# sysctl register map
Vendor: Texas Instruments
Peripheral module from a debugger description file (folder tm4e129xnczad).
Registers are 32-bit, read-write, no defined reset value unless marked. A register's access mark holds for its fields unless they carry their own. Offsets are as the file gives them; lines under a group give offsets from that group; [hi:lo] are bit positions; {n}, {i} and the like mark numbered series; 'fields as' and 'values as' point back to an identical list; <NAME> marks a mode.

## SYSCTL — System Control register addresses
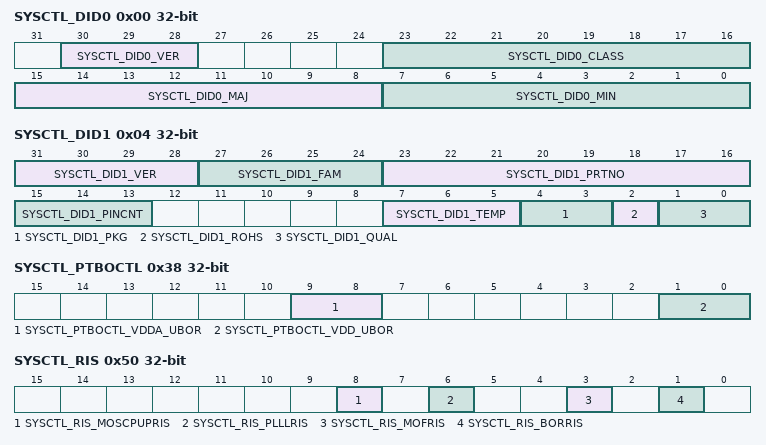
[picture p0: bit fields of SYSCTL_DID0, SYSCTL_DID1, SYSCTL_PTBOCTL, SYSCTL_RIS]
0x00 SYSCTL_DID0 ro — Device Identification 0
  [30:28] SYSCTL_DID0_VER — DID0 Version
    1=Second version of the DID0 register format
  [23:16] SYSCTL_DID0_CLASS — Device Class
    10=SYSCTL_DID0_CLASS_TM4C129 (Tiva(TM) TM4C129-class microcontrollers)
  [15:8] SYSCTL_DID0_MAJ — Major Revision
    0=SYSCTL_DID0_MAJ_REVA (Revision A (initial device)); 1=SYSCTL_DID0_MAJ_REVB (Revision B (first base layer revision)); 2=SYSCTL_DID0_MAJ_REVC (Revision C (second base layer revision))
  [7:0] SYSCTL_DID0_MIN — Minor Revision
    0=Initial device, or a major revision update; 1=First metal layer change; 2=Second metal layer change
0x04 SYSCTL_DID1 ro — Device Identification 1
  [31:28] SYSCTL_DID1_VER — DID1 Version
  [27:24] SYSCTL_DID1_FAM — Family
  [23:16] SYSCTL_DID1_PRTNO — Part Number
  [15:13] SYSCTL_DID1_PINCNT — Package Pin Count
    2=100-pin LQFP package; 3=64-pin LQFP package; 4=144-pin LQFP package; 5=157-pin BGA package; 6=128-pin TQFP package
  [7:5] SYSCTL_DID1_TEMP — Temperature Range
    0=SYSCTL_DID1_TEMP_C (Commercial temperature range); 1=SYSCTL_DID1_TEMP_I (Industrial temperature range); 2=SYSCTL_DID1_TEMP_E (Extended temperature range)
  [4:3] SYSCTL_DID1_PKG — Package Type
    1=SYSCTL_DID1_PKG_QFP (QFP package); 2=SYSCTL_DID1_PKG_BGA (BGA package)
  [2] SYSCTL_DID1_ROHS — RoHS-Compliance
  [1:0] SYSCTL_DID1_QUAL — Qualification Status
    0=SYSCTL_DID1_QUAL_ES (Engineering Sample (unqualified)); 1=SYSCTL_DID1_QUAL_PP (Pilot Production (unqualified)); 2=SYSCTL_DID1_QUAL_FQ (Fully Qualified)
0x38 SYSCTL_PTBOCTL — Power-Temp Brown Out Control
  [9:8] SYSCTL_PTBOCTL_VDDA_UBOR — VDDA under BOR Event Action
    0=SYSCTL_PTBOCTL_VDDA_UBOR_NONE (No Action); 1=SYSCTL_PTBOCTL_VDDA_UBOR_SYSINT (System control interrupt); 2=SYSCTL_PTBOCTL_VDDA_UBOR_NMI (NMI); 3=SYSCTL_PTBOCTL_VDDA_UBOR_RST (Reset)
  [1:0] SYSCTL_PTBOCTL_VDD_UBOR — VDD (VDDS) under BOR Event Action
    0=SYSCTL_PTBOCTL_VDD_UBOR_NONE (No Action); 1=SYSCTL_PTBOCTL_VDD_UBOR_SYSINT (System control interrupt); 2=SYSCTL_PTBOCTL_VDD_UBOR_NMI (NMI); 3=SYSCTL_PTBOCTL_VDD_UBOR_RST (Reset)
0x50 SYSCTL_RIS ro — Raw Interrupt Status
  [8] SYSCTL_RIS_MOSCPUPRIS — MOSC Power Up Raw Interrupt Status
  [6] SYSCTL_RIS_PLLLRIS — PLL Lock Raw Interrupt Status
  [3] SYSCTL_RIS_MOFRIS — Main Oscillator Failure Raw Interrupt Status
  [1] SYSCTL_RIS_BORRIS — Brown-Out Reset Raw Interrupt Status
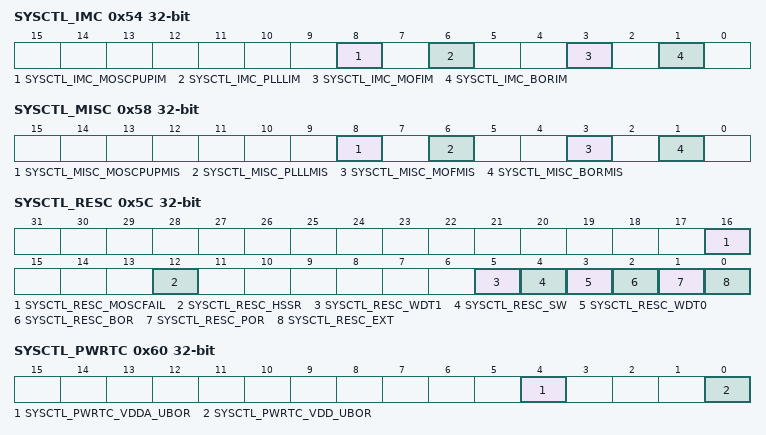
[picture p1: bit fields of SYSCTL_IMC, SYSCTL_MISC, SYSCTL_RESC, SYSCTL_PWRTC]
0x54 SYSCTL_IMC — Interrupt Mask Control
  [8] SYSCTL_IMC_MOSCPUPIM — MOSC Power Up Interrupt Mask
  [6] SYSCTL_IMC_PLLLIM — PLL Lock Interrupt Mask
  [3] SYSCTL_IMC_MOFIM — Main Oscillator Failure Interrupt Mask
  [1] SYSCTL_IMC_BORIM — Brown-Out Reset Interrupt Mask
0x58 SYSCTL_MISC — Masked Interrupt Status and Clear
  [8] SYSCTL_MISC_MOSCPUPMIS — MOSC Power Up Masked Interrupt Status
  [6] SYSCTL_MISC_PLLLMIS — PLL Lock Masked Interrupt Status
  [3] SYSCTL_MISC_MOFMIS — Main Oscillator Failure Masked Interrupt Status
  [1] SYSCTL_MISC_BORMIS — BOR Masked Interrupt Status
0x5C SYSCTL_RESC — Reset Cause
  [16] SYSCTL_RESC_MOSCFAIL — MOSC Failure Reset
  [12] SYSCTL_RESC_HSSR — HSSR Reset
  [5] SYSCTL_RESC_WDT1 — Watchdog Timer 1 Reset
  [4] SYSCTL_RESC_SW — Software Reset
  [3] SYSCTL_RESC_WDT0 — Watchdog Timer 0 Reset
  [2] SYSCTL_RESC_BOR — Brown-Out Reset
  [1] SYSCTL_RESC_POR — Power-On Reset
  [0] SYSCTL_RESC_EXT — External Reset
0x60 SYSCTL_PWRTC — Power-Temperature Cause
  [4] SYSCTL_PWRTC_VDDA_UBOR — VDDA Under BOR Status
  [0] SYSCTL_PWRTC_VDD_UBOR — VDD Under BOR Status
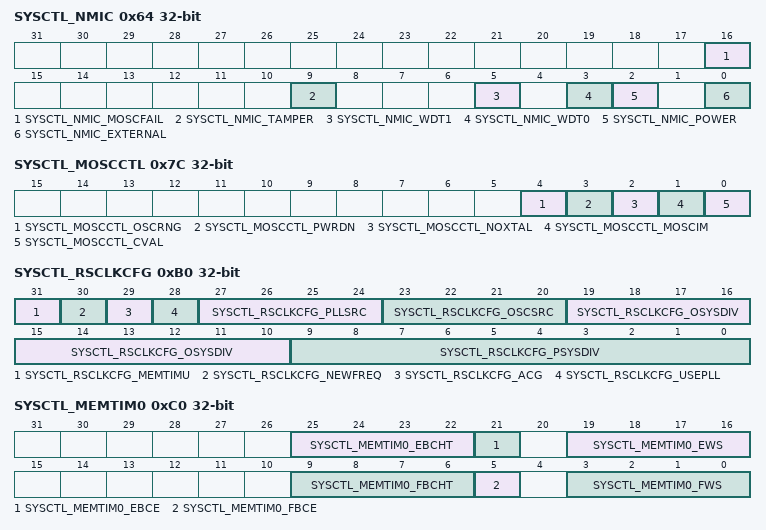
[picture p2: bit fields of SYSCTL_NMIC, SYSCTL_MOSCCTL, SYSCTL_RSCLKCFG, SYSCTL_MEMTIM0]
0x64 SYSCTL_NMIC — NMI Cause Register
  [16] SYSCTL_NMIC_MOSCFAIL — MOSC Failure NMI
  [9] SYSCTL_NMIC_TAMPER — Tamper Event NMI
  [5] SYSCTL_NMIC_WDT1 — Watch Dog Timer (WDT) 1 NMI
  [3] SYSCTL_NMIC_WDT0 — Watch Dog Timer (WDT) 0 NMI
  [2] SYSCTL_NMIC_POWER — Power/Brown Out Event NMI
  [0] SYSCTL_NMIC_EXTERNAL — External Pin NMI
0x7C SYSCTL_MOSCCTL — Main Oscillator Control
  [4] SYSCTL_MOSCCTL_OSCRNG — Oscillator Range
  [3] SYSCTL_MOSCCTL_PWRDN — Power Down
  [2] SYSCTL_MOSCCTL_NOXTAL — No Crystal Connected
  [1] SYSCTL_MOSCCTL_MOSCIM — MOSC Failure Action
  [0] SYSCTL_MOSCCTL_CVAL — Clock Validation for MOSC
0xB0 SYSCTL_RSCLKCFG — Run and Sleep Mode Configuration Register
  [31] SYSCTL_RSCLKCFG_MEMTIMU — Memory Timing Register Update
  [30] SYSCTL_RSCLKCFG_NEWFREQ — New PLLFREQ Accept
  [29] SYSCTL_RSCLKCFG_ACG — Auto Clock Gating
  [28] SYSCTL_RSCLKCFG_USEPLL — Use PLL
  [27:24] SYSCTL_RSCLKCFG_PLLSRC — PLL Source
    0=SYSCTL_RSCLKCFG_PLLSRC_PIOSC (PIOSC is PLL input clock source); 3=SYSCTL_RSCLKCFG_PLLSRC_MOSC (MOSC is the PLL input clock source)
  [23:20] SYSCTL_RSCLKCFG_OSCSRC — Oscillator Source
    0=SYSCTL_RSCLKCFG_OSCSRC_PIOSC (PIOSC is oscillator source); 2=SYSCTL_RSCLKCFG_OSCSRC_LFIOSC (LFIOSC is oscillator source); 3=SYSCTL_RSCLKCFG_OSCSRC_MOSC (MOSC is oscillator source); 4=SYSCTL_RSCLKCFG_OSCSRC_RTC (Hibernation Module RTC Oscillator (RTCOSC))
  [19:10] SYSCTL_RSCLKCFG_OSYSDIV — Oscillator System Clock Divisor
  [9:0] SYSCTL_RSCLKCFG_PSYSDIV — PLL System Clock Divisor
0xC0 SYSCTL_MEMTIM0 — Memory Timing Parameter Register 0 for Main Flash and EEPROM
  [25:22] SYSCTL_MEMTIM0_EBCHT — EEPROM Clock High Time
    0=SYSCTL_MEMTIM0_EBCHT_0_5 (1/2 system clock period); 1=1 system clock period; 2=SYSCTL_MEMTIM0_EBCHT_1_5 (1.5 system clock periods); 3=2 system clock periods; 4=SYSCTL_MEMTIM0_EBCHT_2_5 (2.5 system clock periods); 5=3 system clock periods; 6=SYSCTL_MEMTIM0_EBCHT_3_5 (3.5 system clock periods); 7=4 system clock periods; 8=SYSCTL_MEMTIM0_EBCHT_4_5 (4.5 system clock periods)
  [21] SYSCTL_MEMTIM0_EBCE — EEPROM Bank Clock Edge
  [19:16] SYSCTL_MEMTIM0_EWS — EEPROM Wait States
  [9:6] SYSCTL_MEMTIM0_FBCHT — Flash Bank Clock High Time
    0=SYSCTL_MEMTIM0_FBCHT_0_5 (1/2 system clock period); 1=1 system clock period; 2=SYSCTL_MEMTIM0_FBCHT_1_5 (1.5 system clock periods); 3=2 system clock periods; 4=SYSCTL_MEMTIM0_FBCHT_2_5 (2.5 system clock periods); 5=3 system clock periods; 6=SYSCTL_MEMTIM0_FBCHT_3_5 (3.5 system clock periods); 7=4 system clock periods; 8=SYSCTL_MEMTIM0_FBCHT_4_5 (4.5 system clock periods)
  [5] SYSCTL_MEMTIM0_FBCE — Flash Bank Clock Edge
  [3:0] SYSCTL_MEMTIM0_FWS — Flash Wait State
0x138 SYSCTL_ALTCLKCFG — Alternate Clock Configuration
  [3:0] SYSCTL_ALTCLKCFG_ALTCLK — Alternate Clock Source
    0=SYSCTL_ALTCLKCFG_ALTCLK_PIOSC (PIOSC); 3=SYSCTL_ALTCLKCFG_ALTCLK_RTCOSC (Hibernation Module Real-time clock output (RTCOSC)); 4=SYSCTL_ALTCLKCFG_ALTCLK_LFIOSC (Low-frequency internal oscillator (LFIOSC))
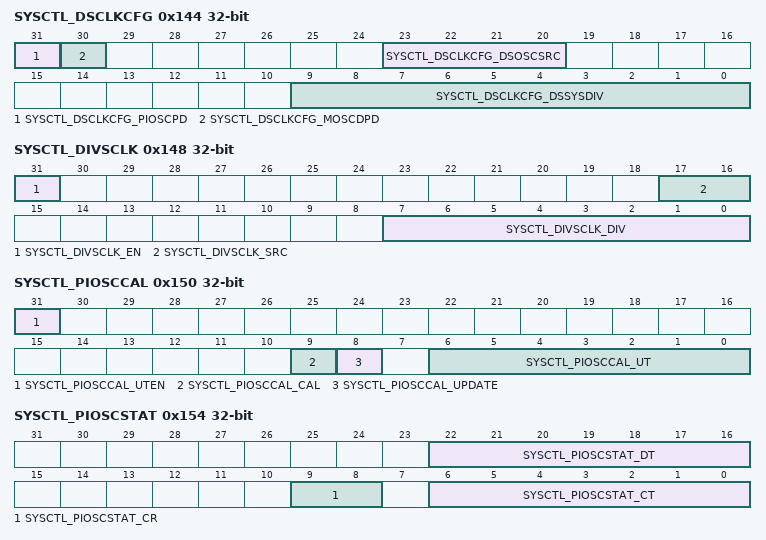
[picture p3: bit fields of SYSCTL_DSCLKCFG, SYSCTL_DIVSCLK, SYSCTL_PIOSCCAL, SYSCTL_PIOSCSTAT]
0x144 SYSCTL_DSCLKCFG — Deep Sleep Clock Configuration Register
  [31] SYSCTL_DSCLKCFG_PIOSCPD — PIOSC Power Down
  [30] SYSCTL_DSCLKCFG_MOSCDPD — MOSC Disable Power Down
  [23:20] SYSCTL_DSCLKCFG_DSOSCSRC — Deep Sleep Oscillator Source
    0=SYSCTL_DSCLKCFG_DSOSCSRC_PIOSC (PIOSC); 2=SYSCTL_DSCLKCFG_DSOSCSRC_LFIOSC (LFIOSC); 3=SYSCTL_DSCLKCFG_DSOSCSRC_MOSC (MOSC); 4=SYSCTL_DSCLKCFG_DSOSCSRC_RTC (Hibernation Module RTCOSC)
  [9:0] SYSCTL_DSCLKCFG_DSSYSDIV — Deep Sleep Clock Divisor
0x148 SYSCTL_DIVSCLK — Divisor and Source Clock Configuration
  [31] SYSCTL_DIVSCLK_EN — DIVSCLK Enable
  [17:16] SYSCTL_DIVSCLK_SRC — Clock Source
    0=SYSCTL_DIVSCLK_SRC_SYSCLK (System Clock); 1=SYSCTL_DIVSCLK_SRC_PIOSC (PIOSC); 2=SYSCTL_DIVSCLK_SRC_MOSC (MOSC)
  [7:0] SYSCTL_DIVSCLK_DIV — Divisor Value
0x14C SYSCTL_SYSPROP ro — System Properties
  [0] SYSCTL_SYSPROP_FPU — FPU Present
0x150 SYSCTL_PIOSCCAL — Precision Internal Oscillator Calibration
  [31] SYSCTL_PIOSCCAL_UTEN — Use User Trim Value
  [9] SYSCTL_PIOSCCAL_CAL — Start Calibration
  [8] SYSCTL_PIOSCCAL_UPDATE — Update Trim
  [6:0] SYSCTL_PIOSCCAL_UT — User Trim Value
0x154 SYSCTL_PIOSCSTAT ro — Precision Internal Oscillator Statistics
  [22:16] SYSCTL_PIOSCSTAT_DT — Default Trim Value
  [9:8] SYSCTL_PIOSCSTAT_CR — Calibration Result
    0=SYSCTL_PIOSCSTAT_CRNONE (Calibration has not been attempted); 1=SYSCTL_PIOSCSTAT_CRPASS (The last calibration operation completed to meet 1% accuracy); 2=SYSCTL_PIOSCSTAT_CRFAIL (The last calibration operation failed to meet 1% accuracy)
  [6:0] SYSCTL_PIOSCSTAT_CT — Calibration Trim Value
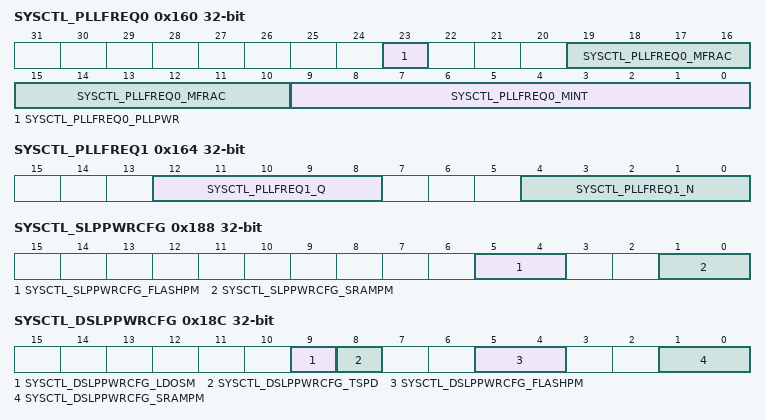
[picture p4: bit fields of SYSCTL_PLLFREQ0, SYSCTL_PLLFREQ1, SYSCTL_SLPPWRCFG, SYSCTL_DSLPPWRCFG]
0x160 SYSCTL_PLLFREQ0 — PLL Frequency 0
  [23] SYSCTL_PLLFREQ0_PLLPWR — PLL Power
  [19:10] SYSCTL_PLLFREQ0_MFRAC — PLL M Fractional Value
  [9:0] SYSCTL_PLLFREQ0_MINT — PLL M Integer Value
0x164 SYSCTL_PLLFREQ1 — PLL Frequency 1
  [12:8] SYSCTL_PLLFREQ1_Q — PLL Q Value
  [4:0] SYSCTL_PLLFREQ1_N — PLL N Value
0x168 SYSCTL_PLLSTAT ro — PLL Status
  [0] SYSCTL_PLLSTAT_LOCK — PLL Lock
0x188 SYSCTL_SLPPWRCFG — Sleep Power Configuration
  [5:4] SYSCTL_SLPPWRCFG_FLASHPM — Flash Power Modes
    0=SYSCTL_SLPPWRCFG_FLASHPM_NRM (Active Mode); 2=SYSCTL_SLPPWRCFG_FLASHPM_SLP (Low Power Mode)
  [1:0] SYSCTL_SLPPWRCFG_SRAMPM — SRAM Power Modes
    0=SYSCTL_SLPPWRCFG_SRAMPM_NRM (Active Mode); 1=SYSCTL_SLPPWRCFG_SRAMPM_SBY (Standby Mode); 3=SYSCTL_SLPPWRCFG_SRAMPM_LP (Low Power Mode)
0x18C SYSCTL_DSLPPWRCFG — Deep-Sleep Power Configuration
  [9] SYSCTL_DSLPPWRCFG_LDOSM — LDO Sleep Mode
  [8] SYSCTL_DSLPPWRCFG_TSPD — Temperature Sense Power Down
  [5:4] SYSCTL_DSLPPWRCFG_FLASHPM — Flash Power Modes
    0=SYSCTL_DSLPPWRCFG_FLASHPM_NRM (Active Mode); 2=SYSCTL_DSLPPWRCFG_FLASHPM_SLP (Low Power Mode)
  [1:0] SYSCTL_DSLPPWRCFG_SRAMPM — SRAM Power Modes
    0=SYSCTL_DSLPPWRCFG_SRAMPM_NRM (Active Mode); 1=SYSCTL_DSLPPWRCFG_SRAMPM_SBY (Standby Mode); 3=SYSCTL_DSLPPWRCFG_SRAMPM_LP (Low Power Mode)
0x1A0 SYSCTL_NVMSTAT ro — Non-Volatile Memory Information
  [0] SYSCTL_NVMSTAT_FWB — 32 Word Flash Write Buffer Available
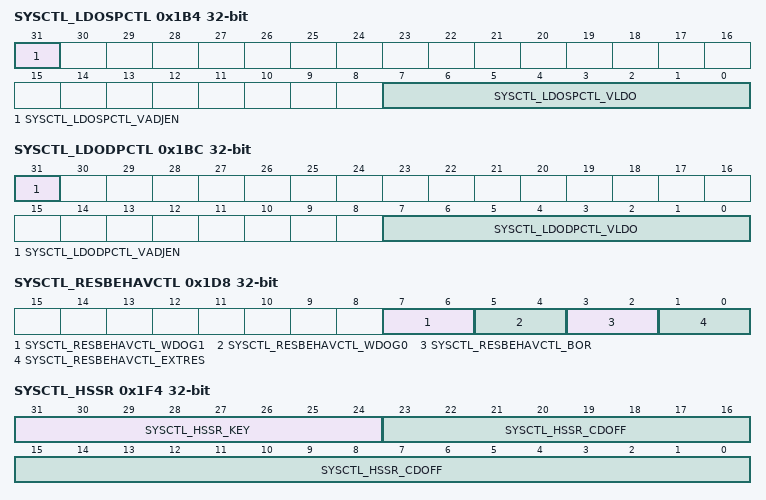
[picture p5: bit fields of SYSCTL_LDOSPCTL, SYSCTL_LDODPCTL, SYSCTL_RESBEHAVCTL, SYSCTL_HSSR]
0x1B4 SYSCTL_LDOSPCTL — LDO Sleep Power Control
  [31] SYSCTL_LDOSPCTL_VADJEN — Voltage Adjust Enable
  [7:0] SYSCTL_LDOSPCTL_VLDO — LDO Output Voltage
    18=SYSCTL_LDOSPCTL_VLDO_0_90V (0.90 V); 19=SYSCTL_LDOSPCTL_VLDO_0_95V (0.95 V); 20=SYSCTL_LDOSPCTL_VLDO_1_00V (1.00 V); 21=SYSCTL_LDOSPCTL_VLDO_1_05V (1.05 V); 22=SYSCTL_LDOSPCTL_VLDO_1_10V (1.10 V); 23=SYSCTL_LDOSPCTL_VLDO_1_15V (1.15 V); 24=SYSCTL_LDOSPCTL_VLDO_1_20V (1.20 V)
0x1BC SYSCTL_LDODPCTL — LDO Deep-Sleep Power Control
  [31] SYSCTL_LDODPCTL_VADJEN — Voltage Adjust Enable
  [7:0] SYSCTL_LDODPCTL_VLDO — LDO Output Voltage
    18=SYSCTL_LDODPCTL_VLDO_0_90V (0.90 V); 19=SYSCTL_LDODPCTL_VLDO_0_95V (0.95 V); 20=SYSCTL_LDODPCTL_VLDO_1_00V (1.00 V); 21=SYSCTL_LDODPCTL_VLDO_1_05V (1.05 V); 22=SYSCTL_LDODPCTL_VLDO_1_10V (1.10 V); 23=SYSCTL_LDODPCTL_VLDO_1_15V (1.15 V); 24=SYSCTL_LDODPCTL_VLDO_1_20V (1.20 V); 25=SYSCTL_LDODPCTL_VLDO_1_25V (1.25 V); 26=SYSCTL_LDODPCTL_VLDO_1_30V (1.30 V); 27=SYSCTL_LDODPCTL_VLDO_1_35V (1.35 V)
0x1D8 SYSCTL_RESBEHAVCTL — Reset Behavior Control Register
  [7:6] SYSCTL_RESBEHAVCTL_WDOG1 — Watchdog 1 Reset Operation
    2=SYSCTL_RESBEHAVCTL_WDOG1_SYSRST (Watchdog 1 issues a system reset. The application starts within 10 us); 3=SYSCTL_RESBEHAVCTL_WDOG1_POR (Watchdog 1 issues a simulated POR sequence. Application starts less than 500 us after deassertion (Default))
  [5:4] SYSCTL_RESBEHAVCTL_WDOG0 — Watchdog 0 Reset Operation
    2=SYSCTL_RESBEHAVCTL_WDOG0_SYSRST (Watchdog 0 issues a system reset. The application starts within 10 us); 3=SYSCTL_RESBEHAVCTL_WDOG0_POR (Watchdog 0 issues a simulated POR sequence. Application starts less than 500 us after deassertion (Default))
  [3:2] SYSCTL_RESBEHAVCTL_BOR — BOR Reset operation
    2=SYSCTL_RESBEHAVCTL_BOR_SYSRST (Brown Out Reset issues system reset. The application starts within 10 us); 3=SYSCTL_RESBEHAVCTL_BOR_POR (Brown Out Reset issues a simulated POR sequence. The application starts less than 500 us after deassertion (Default))
  [1:0] SYSCTL_RESBEHAVCTL_EXTRES — External RST Pin Operation
    2=SYSCTL_RESBEHAVCTL_EXTRES_SYSRST (External RST assertion issues a system reset. The application starts within 10 us); 3=SYSCTL_RESBEHAVCTL_EXTRES_POR (External RST assertion issues a simulated POR sequence. Application starts less than 500 us after deassertion (Default))
0x1F4 SYSCTL_HSSR — Hardware System Service Request
  [31:24] SYSCTL_HSSR_KEY — Write Key
  [23:0] SYSCTL_HSSR_CDOFF — Command Descriptor Pointer
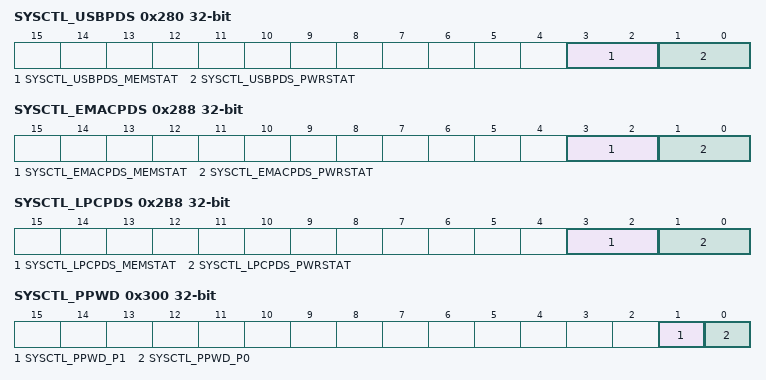
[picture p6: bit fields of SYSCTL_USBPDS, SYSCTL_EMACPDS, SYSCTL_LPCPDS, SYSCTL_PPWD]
0x280 SYSCTL_USBPDS ro — USB Power Domain Status
  [3:2] SYSCTL_USBPDS_MEMSTAT — Memory Array Power Status
    0=SYSCTL_USBPDS_MEMSTAT_OFF (Array OFF); 1=SYSCTL_USBPDS_MEMSTAT_RETAIN (SRAM Retention); 3=SYSCTL_USBPDS_MEMSTAT_ON (Array On)
  [1:0] SYSCTL_USBPDS_PWRSTAT — Power Domain Status
    0=SYSCTL_USBPDS_PWRSTAT_OFF (OFF); 3=SYSCTL_USBPDS_PWRSTAT_ON (ON)
0x284 SYSCTL_USBMPC — USB Memory Power Control
  [1:0] SYSCTL_USBMPC_PWRCTL — Memory Array Power Control
    0=SYSCTL_USBMPC_PWRCTL_OFF (Array OFF); 1=SYSCTL_USBMPC_PWRCTL_RETAIN (SRAM Retention); 3=SYSCTL_USBMPC_PWRCTL_ON (Array On)
0x288 SYSCTL_EMACPDS ro — Ethernet MAC Power Domain Status
  [3:2] SYSCTL_EMACPDS_MEMSTAT — Memory Array Power Status
    0=SYSCTL_EMACPDS_MEMSTAT_OFF (Array OFF); 3=SYSCTL_EMACPDS_MEMSTAT_ON (Array On)
  [1:0] SYSCTL_EMACPDS_PWRSTAT — Power Domain Status
    0=SYSCTL_EMACPDS_PWRSTAT_OFF (OFF); 3=SYSCTL_EMACPDS_PWRSTAT_ON (ON)
0x28C SYSCTL_EMACMPC — Ethernet MAC Memory Power Control
  [1:0] SYSCTL_EMACMPC_PWRCTL — Memory Array Power Control
    0=SYSCTL_EMACMPC_PWRCTL_OFF (Array OFF); 3=SYSCTL_EMACMPC_PWRCTL_ON (Array On)
0x294 SYSCTL_LCDMPC — LCD Memory Power Control
  [1:0] SYSCTL_LCDMPC_PWRCTL — Memory Array Power Control
    0=SYSCTL_LCDMPC_PWRCTL_OFF (Array OFF); 3=SYSCTL_LCDMPC_PWRCTL_ON (Array On)
0x2B8 SYSCTL_LPCPDS ro — LPC Power Domain Status
  [3:2] SYSCTL_LPCPDS_MEMSTAT — Memory Array Power Status
    0=SYSCTL_LPCPDS_MEMSTAT_OFF (Array OFF); 3=SYSCTL_LPCPDS_MEMSTAT_ON (Array On)
  [1:0] SYSCTL_LPCPDS_PWRSTAT — Power Domain Status
    0=SYSCTL_LPCPDS_PWRSTAT_OFF (OFF); 3=SYSCTL_LPCPDS_PWRSTAT_ON (ON)
0x2BC SYSCTL_LPCMPC — LPC Memory Power Control
  [1:0] SYSCTL_LPCMPC_PWRCTL — Memory Array Power Control
    0=SYSCTL_LPCMPC_PWRCTL_OFF (Array OFF); 3=SYSCTL_LPCMPC_PWRCTL_ON (Array On)
0x300 SYSCTL_PPWD ro — Watchdog Timer Peripheral Present
  [1] SYSCTL_PPWD_P1 — Watchdog Timer 1 Present
  [0] SYSCTL_PPWD_P0 — Watchdog Timer 0 Present
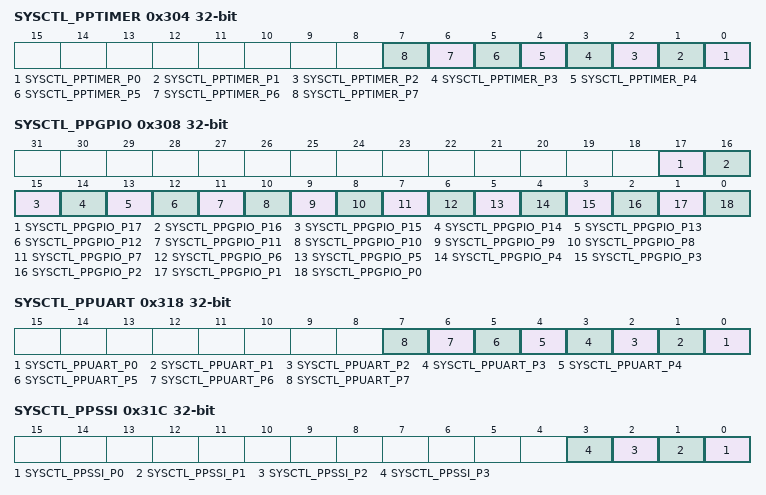
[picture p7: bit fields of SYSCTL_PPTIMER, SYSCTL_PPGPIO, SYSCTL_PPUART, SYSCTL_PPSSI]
0x304 SYSCTL_PPTIMER ro — 16/32-Bit General-Purpose Timer Peripheral Present
  [n] SYSCTL_PPTIMER_P{n} (n=0..7) — 16/32-Bit General-Purpose Timer {n} Present
0x308 SYSCTL_PPGPIO ro — General-Purpose Input/Output Peripheral Present
  [17] SYSCTL_PPGPIO_P17 — GPIO Port T Present
  [16] SYSCTL_PPGPIO_P16 — GPIO Port S Present
  [15] SYSCTL_PPGPIO_P15 — GPIO Port R Present
  [14] SYSCTL_PPGPIO_P14 — GPIO Port Q Present
  [13] SYSCTL_PPGPIO_P13 — GPIO Port P Present
  [12] SYSCTL_PPGPIO_P12 — GPIO Port N Present
  [11] SYSCTL_PPGPIO_P11 — GPIO Port M Present
  [10] SYSCTL_PPGPIO_P10 — GPIO Port L Present
  [9] SYSCTL_PPGPIO_P9 — GPIO Port K Present
  [8] SYSCTL_PPGPIO_P8 — GPIO Port J Present
  [7] SYSCTL_PPGPIO_P7 — GPIO Port H Present
  [6] SYSCTL_PPGPIO_P6 — GPIO Port G Present
  [5] SYSCTL_PPGPIO_P5 — GPIO Port F Present
  [4] SYSCTL_PPGPIO_P4 — GPIO Port E Present
  [3] SYSCTL_PPGPIO_P3 — GPIO Port D Present
  [2] SYSCTL_PPGPIO_P2 — GPIO Port C Present
  [1] SYSCTL_PPGPIO_P1 — GPIO Port B Present
  [0] SYSCTL_PPGPIO_P0 — GPIO Port A Present
0x30C SYSCTL_PPDMA ro — Micro Direct Memory Access Peripheral Present
  [0] SYSCTL_PPDMA_P0 — uDMA Module Present
0x310 SYSCTL_PPEPI ro — EPI Peripheral Present
  [0] SYSCTL_PPEPI_P0 — EPI Module Present
0x314 SYSCTL_PPHIB ro — Hibernation Peripheral Present
  [0] SYSCTL_PPHIB_P0 — Hibernation Module Present
0x318 SYSCTL_PPUART ro — Universal Asynchronous Receiver/Transmitter Peripheral Present
  [n] SYSCTL_PPUART_P{n} (n=0..7) — UART Module {n} Present
0x31C SYSCTL_PPSSI ro — Synchronous Serial Interface Peripheral Present
  [n] SYSCTL_PPSSI_P{n} (n=0..3) — SSI Module {n} Present
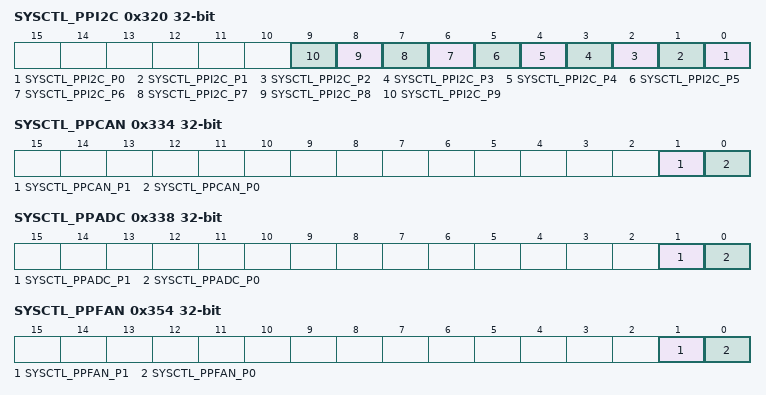
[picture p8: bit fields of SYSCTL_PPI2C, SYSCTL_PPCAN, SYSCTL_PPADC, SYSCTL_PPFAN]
0x320 SYSCTL_PPI2C ro — Inter-Integrated Circuit Peripheral Present
  [n] SYSCTL_PPI2C_P{n} (n=0..9) — I2C Module {n} Present
0x328 SYSCTL_PPUSB ro — Universal Serial Bus Peripheral Present
  [0] SYSCTL_PPUSB_P0 — USB Module Present
0x330 SYSCTL_PPEPHY ro — Ethernet PHY Peripheral Present
  [0] SYSCTL_PPEPHY_P0 — Ethernet PHY Module Present
0x334 SYSCTL_PPCAN ro — Controller Area Network Peripheral Present
  [1] SYSCTL_PPCAN_P1 — CAN Module 1 Present
  [0] SYSCTL_PPCAN_P0 — CAN Module 0 Present
0x338 SYSCTL_PPADC ro — Analog-to-Digital Converter Peripheral Present
  [1] SYSCTL_PPADC_P1 — ADC Module 1 Present
  [0] SYSCTL_PPADC_P0 — ADC Module 0 Present
0x33C SYSCTL_PPACMP ro — Analog Comparator Peripheral Present
  [0] SYSCTL_PPACMP_P0 — Analog Comparator Module Present
0x340 SYSCTL_PPPWM ro — Pulse Width Modulator Peripheral Present
  [0] SYSCTL_PPPWM_P0 — PWM Module 0 Present
0x344 SYSCTL_PPQEI ro — Quadrature Encoder Interface Peripheral Present
  [0] SYSCTL_PPQEI_P0 — QEI Module 0 Present
0x348 SYSCTL_PPLPC ro — Low Pin Count Interface Peripheral Present
  [0] SYSCTL_PPLPC_P0 — LPC Module Present
0x350 SYSCTL_PPPECI ro — Platform Environment Control Interface Peripheral Present
  [0] SYSCTL_PPPECI_P0 — PECI Module Present
0x354 SYSCTL_PPFAN ro — Fan Control Peripheral Present
  [1] SYSCTL_PPFAN_P1 — FAN 1 Module Present
  [0] SYSCTL_PPFAN_P0 — FAN Module 0 Present
0x358 SYSCTL_PPEEPROM ro — EEPROM Peripheral Present
  [0] SYSCTL_PPEEPROM_P0 — EEPROM Module Present
0x35C SYSCTL_PPWTIMER ro — 32/64-Bit Wide General-Purpose Timer Peripheral Present
  [0] SYSCTL_PPWTIMER_P0 — 32/64-Bit Wide General-Purpose Timer 0 Present
0x370 SYSCTL_PPRTS ro — Remote Temperature Sensor Peripheral Present
  [0] SYSCTL_PPRTS_P0 — RTS Module Present
0x374 SYSCTL_PPCCM ro — CRC and Cryptographic Modules Peripheral Present
  [0] SYSCTL_PPCCM_P0 — CRC and Cryptographic Modules Present
0x390 SYSCTL_PPLCD ro — LCD Peripheral Present
  [0] SYSCTL_PPLCD_P0 — LCD Module Present
0x398 SYSCTL_PPOWIRE ro — 1-Wire Peripheral Present
  [0] SYSCTL_PPOWIRE_P0 — 1-Wire Module Present
0x39C SYSCTL_PPEMAC ro — Ethernet MAC Peripheral Present
  [0] SYSCTL_PPEMAC_P0 — Ethernet Controller Module Present
0x3A4 SYSCTL_PPHIM ro — Human Interface Master Peripheral Present
  [0] SYSCTL_PPHIM_P0 — HIM Module Present
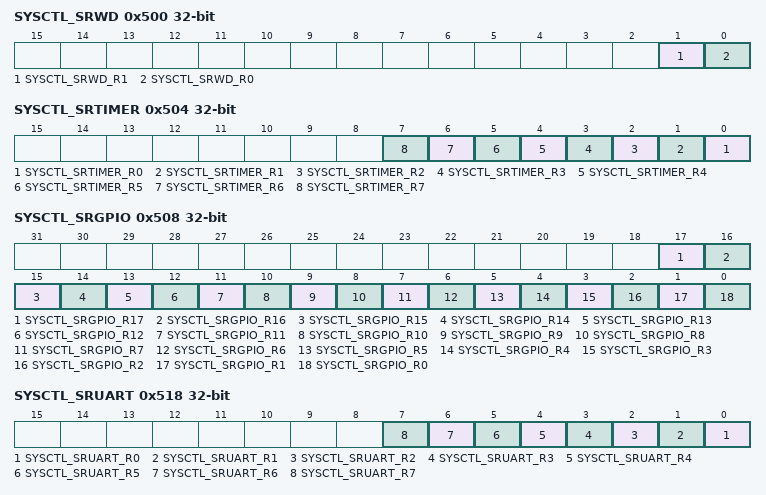
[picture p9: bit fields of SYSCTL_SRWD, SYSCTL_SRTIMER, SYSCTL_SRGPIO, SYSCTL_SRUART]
0x500 SYSCTL_SRWD — Watchdog Timer Software Reset
  [1] SYSCTL_SRWD_R1 — Watchdog Timer 1 Software Reset
  [0] SYSCTL_SRWD_R0 — Watchdog Timer 0 Software Reset
0x504 SYSCTL_SRTIMER — 16/32-Bit General-Purpose Timer Software Reset
  [n] SYSCTL_SRTIMER_R{n} (n=0..7) — 16/32-Bit General-Purpose Timer {n} Software Reset
0x508 SYSCTL_SRGPIO — General-Purpose Input/Output Software Reset
  [17] SYSCTL_SRGPIO_R17 — GPIO Port T Software Reset
  [16] SYSCTL_SRGPIO_R16 — GPIO Port S Software Reset
  [15] SYSCTL_SRGPIO_R15 — GPIO Port R Software Reset
  [14] SYSCTL_SRGPIO_R14 — GPIO Port Q Software Reset
  [13] SYSCTL_SRGPIO_R13 — GPIO Port P Software Reset
  [12] SYSCTL_SRGPIO_R12 — GPIO Port N Software Reset
  [11] SYSCTL_SRGPIO_R11 — GPIO Port M Software Reset
  [10] SYSCTL_SRGPIO_R10 — GPIO Port L Software Reset
  [9] SYSCTL_SRGPIO_R9 — GPIO Port K Software Reset
  [8] SYSCTL_SRGPIO_R8 — GPIO Port J Software Reset
  [7] SYSCTL_SRGPIO_R7 — GPIO Port H Software Reset
  [6] SYSCTL_SRGPIO_R6 — GPIO Port G Software Reset
  [5] SYSCTL_SRGPIO_R5 — GPIO Port F Software Reset
  [4] SYSCTL_SRGPIO_R4 — GPIO Port E Software Reset
  [3] SYSCTL_SRGPIO_R3 — GPIO Port D Software Reset
  [2] SYSCTL_SRGPIO_R2 — GPIO Port C Software Reset
  [1] SYSCTL_SRGPIO_R1 — GPIO Port B Software Reset
  [0] SYSCTL_SRGPIO_R0 — GPIO Port A Software Reset
0x50C SYSCTL_SRDMA — Micro Direct Memory Access Software Reset
  [0] SYSCTL_SRDMA_R0 — uDMA Module Software Reset
0x510 SYSCTL_SREPI — EPI Software Reset
  [0] SYSCTL_SREPI_R0 — EPI Module Software Reset
0x514 SYSCTL_SRHIB — Hibernation Software Reset
  [0] SYSCTL_SRHIB_R0 — Hibernation Module Software Reset
0x518 SYSCTL_SRUART — Universal Asynchronous Receiver/Transmitter Software Reset
  [n] SYSCTL_SRUART_R{n} (n=0..7) — UART Module {n} Software Reset
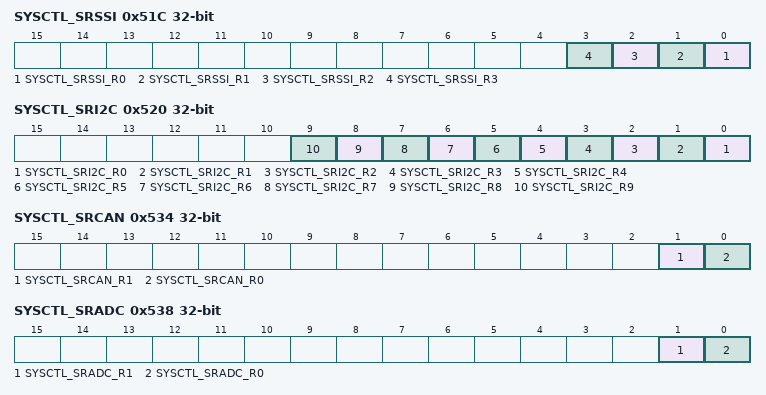
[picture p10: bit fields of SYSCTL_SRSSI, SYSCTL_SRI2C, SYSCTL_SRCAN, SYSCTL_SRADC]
0x51C SYSCTL_SRSSI — Synchronous Serial Interface Software Reset
  [n] SYSCTL_SRSSI_R{n} (n=0..3) — SSI Module {n} Software Reset
0x520 SYSCTL_SRI2C — Inter-Integrated Circuit Software Reset
  [n] SYSCTL_SRI2C_R{n} (n=0..9) — I2C Module {n} Software Reset
0x528 SYSCTL_SRUSB — Universal Serial Bus Software Reset
  [0] SYSCTL_SRUSB_R0 — USB Module Software Reset
0x530 SYSCTL_SREPHY — Ethernet PHY Software Reset
  [0] SYSCTL_SREPHY_R0 — Ethernet PHY Module Software Reset
0x534 SYSCTL_SRCAN — Controller Area Network Software Reset
  [1] SYSCTL_SRCAN_R1 — CAN Module 1 Software Reset
  [0] SYSCTL_SRCAN_R0 — CAN Module 0 Software Reset
0x538 SYSCTL_SRADC — Analog-to-Digital Converter Software Reset
  [1] SYSCTL_SRADC_R1 — ADC Module 1 Software Reset
  [0] SYSCTL_SRADC_R0 — ADC Module 0 Software Reset
0x53C SYSCTL_SRACMP — Analog Comparator Software Reset
  [0] SYSCTL_SRACMP_R0 — Analog Comparator Module 0 Software Reset
0x540 SYSCTL_SRPWM — Pulse Width Modulator Software Reset
  [0] SYSCTL_SRPWM_R0 — PWM Module 0 Software Reset
0x544 SYSCTL_SRQEI — Quadrature Encoder Interface Software Reset
  [0] SYSCTL_SRQEI_R0 — QEI Module 0 Software Reset
0x548 SYSCTL_SRLPC — Low Pin Count Interface Software Reset
  [0] SYSCTL_SRLPC_R0 — LPC Module Software Reset
0x550 SYSCTL_SRPECI — Platform Environment Control Interface Software Reset
  [0] SYSCTL_SRPECI_R0 — PECI Module Software Reset
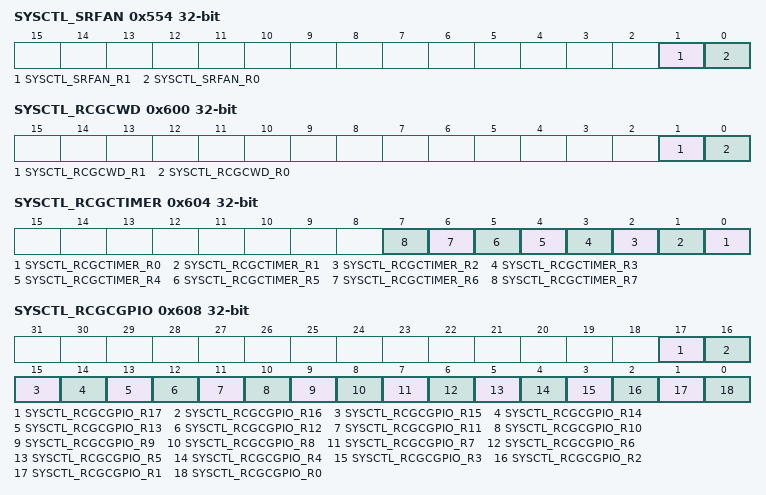
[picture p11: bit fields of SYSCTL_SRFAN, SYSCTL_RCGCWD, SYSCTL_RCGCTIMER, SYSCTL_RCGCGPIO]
0x554 SYSCTL_SRFAN — Fan Software Reset
  [1] SYSCTL_SRFAN_R1 — FAN 1 Module Software Reset
  [0] SYSCTL_SRFAN_R0 — FAN 0 Module Software Reset
0x558 SYSCTL_SREEPROM — EEPROM Software Reset
  [0] SYSCTL_SREEPROM_R0 — EEPROM Module Software Reset
0x574 SYSCTL_SRCCM — CRC and Cryptographic Modules Software Reset
  [0] SYSCTL_SRCCM_R0
0x590 SYSCTL_SRLCD — LCD Controller Software Reset
  [0] SYSCTL_SRLCD_R0 — LCD Module 0 Software Reset
0x598 SYSCTL_SROWIRE — 1-Wire Software Reset
  [0] SYSCTL_SROWIRE_R0 — 1-Wire Module Software Reset
0x59C SYSCTL_SREMAC — Ethernet MAC Software Reset
  [0] SYSCTL_SREMAC_R0 — Ethernet Controller MAC Module 0 Software Reset
0x5A4 SYSCTL_SRHIM — Human Interface Master Software Reset
  [0] SYSCTL_SRHIM_R0 — HIM Module 0 Software Reset
0x600 SYSCTL_RCGCWD — Watchdog Timer Run Mode Clock Gating Control
  [1] SYSCTL_RCGCWD_R1 — Watchdog Timer 1 Run Mode Clock Gating Control
  [0] SYSCTL_RCGCWD_R0 — Watchdog Timer 0 Run Mode Clock Gating Control
0x604 SYSCTL_RCGCTIMER — 16/32-Bit General-Purpose Timer Run Mode Clock Gating Control
  [n] SYSCTL_RCGCTIMER_R{n} (n=0..7) — 16/32-Bit General-Purpose Timer {n} Run Mode Clock Gating Control
0x608 SYSCTL_RCGCGPIO — General-Purpose Input/Output Run Mode Clock Gating Control
  [17] SYSCTL_RCGCGPIO_R17 — GPIO Port T Run Mode Clock Gating Control
  [16] SYSCTL_RCGCGPIO_R16 — GPIO Port S Run Mode Clock Gating Control
  [15] SYSCTL_RCGCGPIO_R15 — GPIO Port R Run Mode Clock Gating Control
  [14] SYSCTL_RCGCGPIO_R14 — GPIO Port Q Run Mode Clock Gating Control
  [13] SYSCTL_RCGCGPIO_R13 — GPIO Port P Run Mode Clock Gating Control
  [12] SYSCTL_RCGCGPIO_R12 — GPIO Port N Run Mode Clock Gating Control
  [11] SYSCTL_RCGCGPIO_R11 — GPIO Port M Run Mode Clock Gating Control
  [10] SYSCTL_RCGCGPIO_R10 — GPIO Port L Run Mode Clock Gating Control
  [9] SYSCTL_RCGCGPIO_R9 — GPIO Port K Run Mode Clock Gating Control
  [8] SYSCTL_RCGCGPIO_R8 — GPIO Port J Run Mode Clock Gating Control
  [7] SYSCTL_RCGCGPIO_R7 — GPIO Port H Run Mode Clock Gating Control
  [6] SYSCTL_RCGCGPIO_R6 — GPIO Port G Run Mode Clock Gating Control
  [5] SYSCTL_RCGCGPIO_R5 — GPIO Port F Run Mode Clock Gating Control
  [4] SYSCTL_RCGCGPIO_R4 — GPIO Port E Run Mode Clock Gating Control
  [3] SYSCTL_RCGCGPIO_R3 — GPIO Port D Run Mode Clock Gating Control
  [2] SYSCTL_RCGCGPIO_R2 — GPIO Port C Run Mode Clock Gating Control
  [1] SYSCTL_RCGCGPIO_R1 — GPIO Port B Run Mode Clock Gating Control
  [0] SYSCTL_RCGCGPIO_R0 — GPIO Port A Run Mode Clock Gating Control
0x60C SYSCTL_RCGCDMA — Micro Direct Memory Access Run Mode Clock Gating Control
  [0] SYSCTL_RCGCDMA_R0 — uDMA Module Run Mode Clock Gating Control
0x610 SYSCTL_RCGCEPI — EPI Run Mode Clock Gating Control
  [0] SYSCTL_RCGCEPI_R0 — EPI Module Run Mode Clock Gating Control
0x614 SYSCTL_RCGCHIB — Hibernation Run Mode Clock Gating Control
  [0] SYSCTL_RCGCHIB_R0 — Hibernation Module Run Mode Clock Gating Control
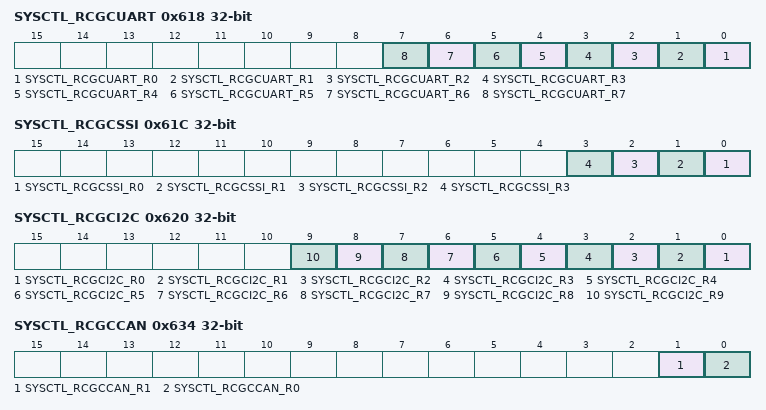
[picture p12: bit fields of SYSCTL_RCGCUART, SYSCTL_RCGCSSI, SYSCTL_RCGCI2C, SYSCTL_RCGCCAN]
0x618 SYSCTL_RCGCUART — Universal Asynchronous Receiver/Transmitter Run Mode Clock Gating Control
  [n] SYSCTL_RCGCUART_R{n} (n=0..7) — UART Module {n} Run Mode Clock Gating Control
0x61C SYSCTL_RCGCSSI — Synchronous Serial Interface Run Mode Clock Gating Control
  [n] SYSCTL_RCGCSSI_R{n} (n=0..3) — SSI Module {n} Run Mode Clock Gating Control
0x620 SYSCTL_RCGCI2C — Inter-Integrated Circuit Run Mode Clock Gating Control
  [n] SYSCTL_RCGCI2C_R{n} (n=0..9) — I2C Module {n} Run Mode Clock Gating Control
0x628 SYSCTL_RCGCUSB — Universal Serial Bus Run Mode Clock Gating Control
  [0] SYSCTL_RCGCUSB_R0 — USB Module Run Mode Clock Gating Control
0x630 SYSCTL_RCGCEPHY — Ethernet PHY Run Mode Clock Gating Control
  [0] SYSCTL_RCGCEPHY_R0 — Ethernet PHY Module Run Mode Clock Gating Control
0x634 SYSCTL_RCGCCAN — Controller Area Network Run Mode Clock Gating Control
  [1] SYSCTL_RCGCCAN_R1 — CAN Module 1 Run Mode Clock Gating Control
  [0] SYSCTL_RCGCCAN_R0 — CAN Module 0 Run Mode Clock Gating Control
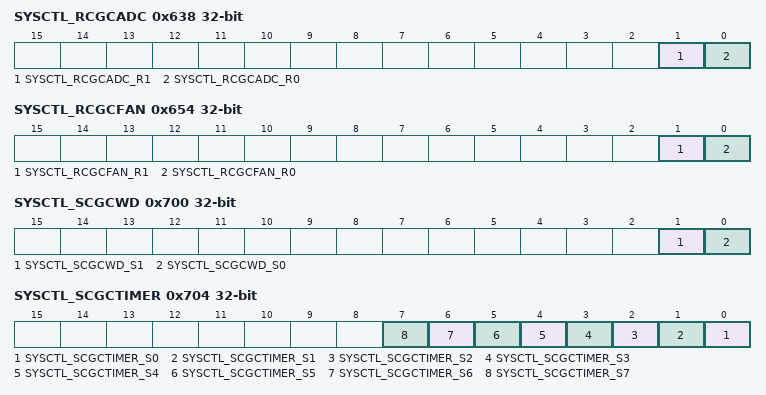
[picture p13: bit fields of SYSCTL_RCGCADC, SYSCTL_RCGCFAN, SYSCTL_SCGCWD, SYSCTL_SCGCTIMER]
0x638 SYSCTL_RCGCADC — Analog-to-Digital Converter Run Mode Clock Gating Control
  [1] SYSCTL_RCGCADC_R1 — ADC Module 1 Run Mode Clock Gating Control
  [0] SYSCTL_RCGCADC_R0 — ADC Module 0 Run Mode Clock Gating Control
0x63C SYSCTL_RCGCACMP — Analog Comparator Run Mode Clock Gating Control
  [0] SYSCTL_RCGCACMP_R0 — Analog Comparator Module 0 Run Mode Clock Gating Control
0x640 SYSCTL_RCGCPWM — Pulse Width Modulator Run Mode Clock Gating Control
  [0] SYSCTL_RCGCPWM_R0 — PWM Module 0 Run Mode Clock Gating Control
0x644 SYSCTL_RCGCQEI — Quadrature Encoder Interface Run Mode Clock Gating Control
  [0] SYSCTL_RCGCQEI_R0 — QEI Module 0 Run Mode Clock Gating Control
0x648 SYSCTL_RCGCLPC — Low Pin Count Interface Run Mode Clock Gating Control
  [0] SYSCTL_RCGCLPC_R0 — LPC Module Run Mode Clock Gating Control
0x650 SYSCTL_RCGCPECI — Platform Environment Control Interface Run Mode Clock Gating Control
  [0] SYSCTL_RCGCPECI_R0 — PECI Module Run Mode Clock Gating Control
0x654 SYSCTL_RCGCFAN — Fan Run Mode Clock Gating Control
  [1] SYSCTL_RCGCFAN_R1 — FAN Module 1 Run Mode Clock Gating Control
  [0] SYSCTL_RCGCFAN_R0 — FAN Module 0 Run Mode Clock Gating Control
0x658 SYSCTL_RCGCEEPROM — EEPROM Run Mode Clock Gating Control
  [0] SYSCTL_RCGCEEPROM_R0 — EEPROM Module Run Mode Clock Gating Control
0x674 SYSCTL_RCGCCCM — CRC and Cryptographic Modules Run Mode Clock Gating Control
  [0] SYSCTL_RCGCCCM_R0
0x690 SYSCTL_RCGCLCD — LCD Controller Run Mode Clock Gating Control
  [0] SYSCTL_RCGCLCD_R0 — LCD Controller Module 0 Run Mode Clock Gating Control
0x698 SYSCTL_RCGCOWIRE — 1-Wire Run Mode Clock Gating Control
  [0] SYSCTL_RCGCOWIRE_R0 — 1-Wire Module 0 Run Mode Clock Gating Control
0x69C SYSCTL_RCGCEMAC — Ethernet MAC Run Mode Clock Gating Control
  [0] SYSCTL_RCGCEMAC_R0 — Ethernet MAC Module 0 Run Mode Clock Gating Control
0x6A4 SYSCTL_RCGCHIM — Human Interface Master Run Mode Clock Gating Control
  [0] SYSCTL_RCGCHIM_R0 — HIM Module 0 Run Mode Clock Gating Control
0x700 SYSCTL_SCGCWD — Watchdog Timer Sleep Mode Clock Gating Control
  [1] SYSCTL_SCGCWD_S1 — Watchdog Timer 1 Sleep Mode Clock Gating Control
  [0] SYSCTL_SCGCWD_S0 — Watchdog Timer 0 Sleep Mode Clock Gating Control
0x704 SYSCTL_SCGCTIMER — 16/32-Bit General-Purpose Timer Sleep Mode Clock Gating Control
  [n] SYSCTL_SCGCTIMER_S{n} (n=0..7) — 16/32-Bit General-Purpose Timer {n} Sleep Mode Clock Gating Control
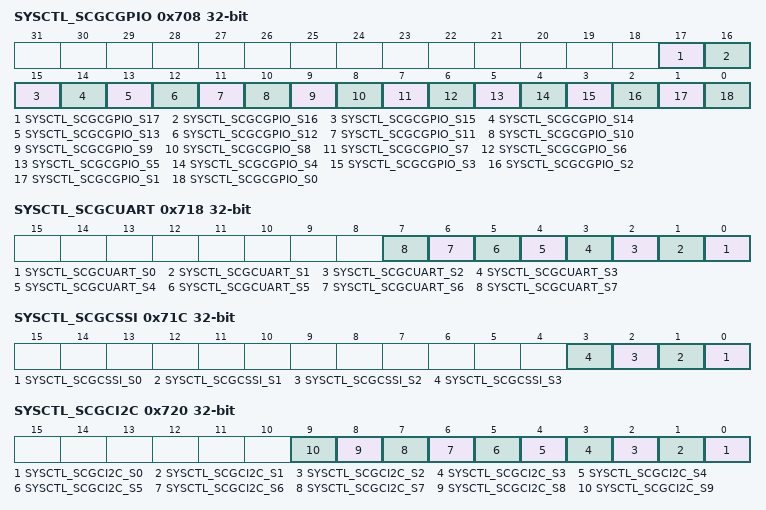
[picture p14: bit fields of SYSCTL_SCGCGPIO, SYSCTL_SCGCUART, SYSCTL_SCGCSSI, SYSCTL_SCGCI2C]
0x708 SYSCTL_SCGCGPIO — General-Purpose Input/Output Sleep Mode Clock Gating Control
  [17] SYSCTL_SCGCGPIO_S17 — GPIO Port T Sleep Mode Clock Gating Control
  [16] SYSCTL_SCGCGPIO_S16 — GPIO Port S Sleep Mode Clock Gating Control
  [15] SYSCTL_SCGCGPIO_S15 — GPIO Port R Sleep Mode Clock Gating Control
  [14] SYSCTL_SCGCGPIO_S14 — GPIO Port Q Sleep Mode Clock Gating Control
  [13] SYSCTL_SCGCGPIO_S13 — GPIO Port P Sleep Mode Clock Gating Control
  [12] SYSCTL_SCGCGPIO_S12 — GPIO Port N Sleep Mode Clock Gating Control
  [11] SYSCTL_SCGCGPIO_S11 — GPIO Port M Sleep Mode Clock Gating Control
  [10] SYSCTL_SCGCGPIO_S10 — GPIO Port L Sleep Mode Clock Gating Control
  [9] SYSCTL_SCGCGPIO_S9 — GPIO Port K Sleep Mode Clock Gating Control
  [8] SYSCTL_SCGCGPIO_S8 — GPIO Port J Sleep Mode Clock Gating Control
  [7] SYSCTL_SCGCGPIO_S7 — GPIO Port H Sleep Mode Clock Gating Control
  [6] SYSCTL_SCGCGPIO_S6 — GPIO Port G Sleep Mode Clock Gating Control
  [5] SYSCTL_SCGCGPIO_S5 — GPIO Port F Sleep Mode Clock Gating Control
  [4] SYSCTL_SCGCGPIO_S4 — GPIO Port E Sleep Mode Clock Gating Control
  [3] SYSCTL_SCGCGPIO_S3 — GPIO Port D Sleep Mode Clock Gating Control
  [2] SYSCTL_SCGCGPIO_S2 — GPIO Port C Sleep Mode Clock Gating Control
  [1] SYSCTL_SCGCGPIO_S1 — GPIO Port B Sleep Mode Clock Gating Control
  [0] SYSCTL_SCGCGPIO_S0 — GPIO Port A Sleep Mode Clock Gating Control
0x70C SYSCTL_SCGCDMA — Micro Direct Memory Access Sleep Mode Clock Gating Control
  [0] SYSCTL_SCGCDMA_S0 — uDMA Module Sleep Mode Clock Gating Control
0x710 SYSCTL_SCGCEPI — EPI Sleep Mode Clock Gating Control
  [0] SYSCTL_SCGCEPI_S0 — EPI Module Sleep Mode Clock Gating Control
0x714 SYSCTL_SCGCHIB — Hibernation Sleep Mode Clock Gating Control
  [0] SYSCTL_SCGCHIB_S0 — Hibernation Module Sleep Mode Clock Gating Control
0x718 SYSCTL_SCGCUART — Universal Asynchronous Receiver/Transmitter Sleep Mode Clock Gating Control
  [n] SYSCTL_SCGCUART_S{n} (n=0..7) — UART Module {n} Sleep Mode Clock Gating Control
0x71C SYSCTL_SCGCSSI — Synchronous Serial Interface Sleep Mode Clock Gating Control
  [n] SYSCTL_SCGCSSI_S{n} (n=0..3) — SSI Module {n} Sleep Mode Clock Gating Control
0x720 SYSCTL_SCGCI2C — Inter-Integrated Circuit Sleep Mode Clock Gating Control
  [n] SYSCTL_SCGCI2C_S{n} (n=0..9) — I2C Module {n} Sleep Mode Clock Gating Control
0x728 SYSCTL_SCGCUSB — Universal Serial Bus Sleep Mode Clock Gating Control
  [0] SYSCTL_SCGCUSB_S0 — USB Module Sleep Mode Clock Gating Control
0x730 SYSCTL_SCGCEPHY — Ethernet PHY Sleep Mode Clock Gating Control
  [0] SYSCTL_SCGCEPHY_S0 — PHY Module Sleep Mode Clock Gating Control
0x734 SYSCTL_SCGCCAN — Controller Area Network Sleep Mode Clock Gating Control
  [1] SYSCTL_SCGCCAN_S1 — CAN Module 1 Sleep Mode Clock Gating Control
  [0] SYSCTL_SCGCCAN_S0 — CAN Module 0 Sleep Mode Clock Gating Control
0x738 SYSCTL_SCGCADC — Analog-to-Digital Converter Sleep Mode Clock Gating Control
  [1] SYSCTL_SCGCADC_S1 — ADC Module 1 Sleep Mode Clock Gating Control
  [0] SYSCTL_SCGCADC_S0 — ADC Module 0 Sleep Mode Clock Gating Control
0x73C SYSCTL_SCGCACMP — Analog Comparator Sleep Mode Clock Gating Control
  [0] SYSCTL_SCGCACMP_S0 — Analog Comparator Module 0 Sleep Mode Clock Gating Control
0x740 SYSCTL_SCGCPWM — Pulse Width Modulator Sleep Mode Clock Gating Control
  [0] SYSCTL_SCGCPWM_S0 — PWM Module 0 Sleep Mode Clock Gating Control
0x744 SYSCTL_SCGCQEI — Quadrature Encoder Interface Sleep Mode Clock Gating Control
  [0] SYSCTL_SCGCQEI_S0 — QEI Module 0 Sleep Mode Clock Gating Control
0x748 SYSCTL_SCGCLPC — Low Pin Count Interface Sleep Mode Clock Gating Control
  [0] SYSCTL_SCGCLPC_S0 — LPC Module Sleep Mode Clock Gating Control
0x750 SYSCTL_SCGCPECI — Platform Environment Control Interface Sleep Mode Clock Gating Control
  [0] SYSCTL_SCGCPECI_S0 — PECI Module Sleep Mode Clock Gating Control
0x754 SYSCTL_SCGCFAN — Fan Sleep Mode Clock Gating Control
  [1] SYSCTL_SCGCFAN_S1 — FAN Module 1 Sleep Mode Clock Gating Control
  [0] SYSCTL_SCGCFAN_S0 — FAN Module Sleep Mode Clock Gating Control
0x758 SYSCTL_SCGCEEPROM — EEPROM Sleep Mode Clock Gating Control
  [0] SYSCTL_SCGCEEPROM_S0 — EEPROM Module Sleep Mode Clock Gating Control
0x774 SYSCTL_SCGCCCM — CRC and Cryptographic Modules Sleep Mode Clock Gating Control
  [0] SYSCTL_SCGCCCM_S0
0x790 SYSCTL_SCGCLCD — LCD Controller Sleep Mode Clock Gating Control
  [0] SYSCTL_SCGCLCD_S0 — LCD Controller Module 0 Sleep Mode Clock Gating Control
0x798 SYSCTL_SCGCOWIRE — 1-Wire Sleep Mode Clock Gating Control
  [0] SYSCTL_SCGCOWIRE_S0 — 1-Wire Module 0 Sleep Mode Clock Gating Control
0x79C SYSCTL_SCGCEMAC — Ethernet MAC Sleep Mode Clock Gating Control
  [0] SYSCTL_SCGCEMAC_S0 — Ethernet MAC Module 0 Sleep Mode Clock Gating Control
0x7A4 SYSCTL_SCGCHIM — Human Interface Master Sleep Mode Clock Gating Control
  [0] SYSCTL_SCGCHIM_S0 — HIM Module 0 Sleep Mode Clock Gating Control
0x800 SYSCTL_DCGCWD — Watchdog Timer Deep-Sleep Mode Clock Gating Control
  [1] SYSCTL_DCGCWD_D1 — Watchdog Timer 1 Deep-Sleep Mode Clock Gating Control
  [0] SYSCTL_DCGCWD_D0 — Watchdog Timer 0 Deep-Sleep Mode Clock Gating Control
0x804 SYSCTL_DCGCTIMER — 16/32-Bit General-Purpose Timer Deep-Sleep Mode Clock Gating Control
  [n] SYSCTL_DCGCTIMER_D{n} (n=0..7) — 16/32-Bit General-Purpose Timer {n} Deep-Sleep Mode Clock Gating Control
0x808 SYSCTL_DCGCGPIO — General-Purpose Input/Output Deep-Sleep Mode Clock Gating Control
  [17] SYSCTL_DCGCGPIO_D17 — GPIO Port T Deep-Sleep Mode Clock Gating Control
  [16] SYSCTL_DCGCGPIO_D16 — GPIO Port S Deep-Sleep Mode Clock Gating Control
  [15] SYSCTL_DCGCGPIO_D15 — GPIO Port R Deep-Sleep Mode Clock Gating Control
  [14] SYSCTL_DCGCGPIO_D14 — GPIO Port Q Deep-Sleep Mode Clock Gating Control
  [13] SYSCTL_DCGCGPIO_D13 — GPIO Port P Deep-Sleep Mode Clock Gating Control
  [12] SYSCTL_DCGCGPIO_D12 — GPIO Port N Deep-Sleep Mode Clock Gating Control
  [11] SYSCTL_DCGCGPIO_D11 — GPIO Port M Deep-Sleep Mode Clock Gating Control
  [10] SYSCTL_DCGCGPIO_D10 — GPIO Port L Deep-Sleep Mode Clock Gating Control
  [9] SYSCTL_DCGCGPIO_D9 — GPIO Port K Deep-Sleep Mode Clock Gating Control
  [8] SYSCTL_DCGCGPIO_D8 — GPIO Port J Deep-Sleep Mode Clock Gating Control
  [7] SYSCTL_DCGCGPIO_D7 — GPIO Port H Deep-Sleep Mode Clock Gating Control
  [6] SYSCTL_DCGCGPIO_D6 — GPIO Port G Deep-Sleep Mode Clock Gating Control
  [5] SYSCTL_DCGCGPIO_D5 — GPIO Port F Deep-Sleep Mode Clock Gating Control
  [4] SYSCTL_DCGCGPIO_D4 — GPIO Port E Deep-Sleep Mode Clock Gating Control
  [3] SYSCTL_DCGCGPIO_D3 — GPIO Port D Deep-Sleep Mode Clock Gating Control
  [2] SYSCTL_DCGCGPIO_D2 — GPIO Port C Deep-Sleep Mode Clock Gating Control
  [1] SYSCTL_DCGCGPIO_D1 — GPIO Port B Deep-Sleep Mode Clock Gating Control
  [0] SYSCTL_DCGCGPIO_D0 — GPIO Port A Deep-Sleep Mode Clock Gating Control
0x80C SYSCTL_DCGCDMA — Micro Direct Memory Access Deep-Sleep Mode Clock Gating Control
  [0] SYSCTL_DCGCDMA_D0 — uDMA Module Deep-Sleep Mode Clock Gating Control
0x810 SYSCTL_DCGCEPI — EPI Deep-Sleep Mode Clock Gating Control
  [0] SYSCTL_DCGCEPI_D0 — EPI Module Deep-Sleep Mode Clock Gating Control
0x814 SYSCTL_DCGCHIB — Hibernation Deep-Sleep Mode Clock Gating Control
  [0] SYSCTL_DCGCHIB_D0 — Hibernation Module Deep-Sleep Mode Clock Gating Control
0x818 SYSCTL_DCGCUART — Universal Asynchronous Receiver/Transmitter Deep-Sleep Mode Clock Gating Control
  [n] SYSCTL_DCGCUART_D{n} (n=0..7) — UART Module {n} Deep-Sleep Mode Clock Gating Control
0x81C SYSCTL_DCGCSSI — Synchronous Serial Interface Deep-Sleep Mode Clock Gating Control
  [n] SYSCTL_DCGCSSI_D{n} (n=0..3) — SSI Module {n} Deep-Sleep Mode Clock Gating Control
0x820 SYSCTL_DCGCI2C — Inter-Integrated Circuit Deep-Sleep Mode Clock Gating Control
  [n] SYSCTL_DCGCI2C_D{n} (n=0..9) — I2C Module {n} Deep-Sleep Mode Clock Gating Control
0x828 SYSCTL_DCGCUSB — Universal Serial Bus Deep-Sleep Mode Clock Gating Control
  [0] SYSCTL_DCGCUSB_D0 — USB Module Deep-Sleep Mode Clock Gating Control
0x830 SYSCTL_DCGCEPHY — Ethernet PHY Deep-Sleep Mode Clock Gating Control
  [0] SYSCTL_DCGCEPHY_D0 — PHY Module Deep-Sleep Mode Clock Gating Control
0x834 SYSCTL_DCGCCAN — Controller Area Network Deep-Sleep Mode Clock Gating Control
  [1] SYSCTL_DCGCCAN_D1 — CAN Module 1 Deep-Sleep Mode Clock Gating Control
  [0] SYSCTL_DCGCCAN_D0 — CAN Module 0 Deep-Sleep Mode Clock Gating Control
0x838 SYSCTL_DCGCADC — Analog-to-Digital Converter Deep-Sleep Mode Clock Gating Control
  [1] SYSCTL_DCGCADC_D1 — ADC Module 1 Deep-Sleep Mode Clock Gating Control
  [0] SYSCTL_DCGCADC_D0 — ADC Module 0 Deep-Sleep Mode Clock Gating Control
0x83C SYSCTL_DCGCACMP — Analog Comparator Deep-Sleep Mode Clock Gating Control
  [0] SYSCTL_DCGCACMP_D0 — Analog Comparator Module 0 Deep-Sleep Mode Clock Gating Control
0x840 SYSCTL_DCGCPWM — Pulse Width Modulator Deep-Sleep Mode Clock Gating Control
  [0] SYSCTL_DCGCPWM_D0 — PWM Module 0 Deep-Sleep Mode Clock Gating Control
0x844 SYSCTL_DCGCQEI — Quadrature Encoder Interface Deep-Sleep Mode Clock Gating Control
  [0] SYSCTL_DCGCQEI_D0 — QEI Module 0 Deep-Sleep Mode Clock Gating Control
0x848 SYSCTL_DCGCLPC — Low Pin Count Interface Deep-Sleep Mode Clock Gating Control
  [0] SYSCTL_DCGCLPC_D0 — LPC Module Deep-Sleep Mode Clock Gating Control
0x850 SYSCTL_DCGCPECI — Platform Environment Control Interface Deep-Sleep Mode Clock Gating Control
  [0] SYSCTL_DCGCPECI_D0 — PECI Module Deep-Sleep Mode Clock Gating Control
0x854 SYSCTL_DCGCFAN — Fan Deep-Sleep Mode Clock Gating Control
  [1] SYSCTL_DCGCFAN_D1 — FAN Module 1 Deep-Sleep Mode Clock Gating Control
  [0] SYSCTL_DCGCFAN_D0 — FAN Module 0 Deep-Sleep Mode Clock Gating Control
0x858 SYSCTL_DCGCEEPROM — EEPROM Deep-Sleep Mode Clock Gating Control
  [0] SYSCTL_DCGCEEPROM_D0 — EEPROM Module Deep-Sleep Mode Clock Gating Control
0x874 SYSCTL_DCGCCCM — CRC and Cryptographic Modules Deep-Sleep Mode Clock Gating Control
  [0] SYSCTL_DCGCCCM_D0
0x890 SYSCTL_DCGCLCD — LCD Controller Deep-Sleep Mode Clock Gating Control
  [0] SYSCTL_DCGCLCD_D0 — LCD Controller Module 0 Deep-Sleep Mode Clock Gating Control
0x898 SYSCTL_DCGCOWIRE — 1-Wire Deep-Sleep Mode Clock Gating Control
  [0] SYSCTL_DCGCOWIRE_D0 — 1-Wire Module 0 Deep-Sleep Mode Clock Gating Control
0x89C SYSCTL_DCGCEMAC — Ethernet MAC Deep-Sleep Mode Clock Gating Control
  [0] SYSCTL_DCGCEMAC_D0 — Ethernet MAC Module 0 Deep-Sleep Mode Clock Gating Control
0x8A4 SYSCTL_DCGCHIM — Human Interface Master Deep-Sleep Mode Clock Gating Control
  [0] SYSCTL_DCGCHIM_D0 — HIM Module 0 Deep-Sleep Mode Clock Gating Control
0x900 SYSCTL_PCWD — Watchdog Timer Power Control
  [1] SYSCTL_PCWD_P1 — Watchdog Timer 1 Power Control
  [0] SYSCTL_PCWD_P0 — Watchdog Timer 0 Power Control
0x904 SYSCTL_PCTIMER — 16/32-Bit General-Purpose Timer Power Control
  [n] SYSCTL_PCTIMER_P{n} (n=0..7) — General-Purpose Timer {n} Power Control
0x908 SYSCTL_PCGPIO — General-Purpose Input/Output Power Control
  [17] SYSCTL_PCGPIO_P17 — GPIO Port T Power Control
  [16] SYSCTL_PCGPIO_P16 — GPIO Port S Power Control
  [15] SYSCTL_PCGPIO_P15 — GPIO Port R Power Control
  [14] SYSCTL_PCGPIO_P14 — GPIO Port Q Power Control
  [13] SYSCTL_PCGPIO_P13 — GPIO Port P Power Control
  [12] SYSCTL_PCGPIO_P12 — GPIO Port N Power Control
  [11] SYSCTL_PCGPIO_P11 — GPIO Port M Power Control
  [10] SYSCTL_PCGPIO_P10 — GPIO Port L Power Control
  [9] SYSCTL_PCGPIO_P9 — GPIO Port K Power Control
  [8] SYSCTL_PCGPIO_P8 — GPIO Port J Power Control
  [7] SYSCTL_PCGPIO_P7 — GPIO Port H Power Control
  [6] SYSCTL_PCGPIO_P6 — GPIO Port G Power Control
  [5] SYSCTL_PCGPIO_P5 — GPIO Port F Power Control
  [4] SYSCTL_PCGPIO_P4 — GPIO Port E Power Control
  [3] SYSCTL_PCGPIO_P3 — GPIO Port D Power Control
  [2] SYSCTL_PCGPIO_P2 — GPIO Port C Power Control
  [1] SYSCTL_PCGPIO_P1 — GPIO Port B Power Control
  [0] SYSCTL_PCGPIO_P0 — GPIO Port A Power Control
0x90C SYSCTL_PCDMA — Micro Direct Memory Access Power Control
  [0] SYSCTL_PCDMA_P0 — uDMA Module Power Control
0x910 SYSCTL_PCEPI — External Peripheral Interface Power Control
  [0] SYSCTL_PCEPI_P0 — EPI Module Power Control
0x914 SYSCTL_PCHIB — Hibernation Power Control
  [0] SYSCTL_PCHIB_P0 — Hibernation Module Power Control
0x918 SYSCTL_PCUART — Universal Asynchronous Receiver/Transmitter Power Control
  [n] SYSCTL_PCUART_P{n} (n=0..7) — UART Module {n} Power Control
0x91C SYSCTL_PCSSI — Synchronous Serial Interface Power Control
  [n] SYSCTL_PCSSI_P{n} (n=0..3) — SSI Module {n} Power Control
0x920 SYSCTL_PCI2C — Inter-Integrated Circuit Power Control
  [n] SYSCTL_PCI2C_P{n} (n=0..9) — I2C Module {n} Power Control
0x928 SYSCTL_PCUSB — Universal Serial Bus Power Control
  [0] SYSCTL_PCUSB_P0 — USB Module Power Control
0x930 SYSCTL_PCEPHY — Ethernet PHY Power Control
  [0] SYSCTL_PCEPHY_P0 — Ethernet PHY Module Power Control
0x934 SYSCTL_PCCAN — Controller Area Network Power Control
  [1] SYSCTL_PCCAN_P1 — CAN Module 1 Power Control
  [0] SYSCTL_PCCAN_P0 — CAN Module 0 Power Control
0x938 SYSCTL_PCADC — Analog-to-Digital Converter Power Control
  [1] SYSCTL_PCADC_P1 — ADC Module 1 Power Control
  [0] SYSCTL_PCADC_P0 — ADC Module 0 Power Control
0x93C SYSCTL_PCACMP — Analog Comparator Power Control
  [0] SYSCTL_PCACMP_P0 — Analog Comparator Module 0 Power Control
0x940 SYSCTL_PCPWM — Pulse Width Modulator Power Control
  [0] SYSCTL_PCPWM_P0 — PWM Module 0 Power Control
0x944 SYSCTL_PCQEI — Quadrature Encoder Interface Power Control
  [0] SYSCTL_PCQEI_P0 — QEI Module 0 Power Control
0x948 SYSCTL_PCLPC — Low Pin Count Interface Power Control
  [0] SYSCTL_PCLPC_P0 — LPC Module Power Control
0x950 SYSCTL_PCPECI — Platform Environment Control Interface Power Control
  [0] SYSCTL_PCPECI_P0 — PECI Module Power Control
0x954 SYSCTL_PCFAN — Fan Power Control
  [1] SYSCTL_PCFAN_P1 — FAN Module 1 Power Control
  [0] SYSCTL_PCFAN_P0 — FAN Module 0 Power Control
0x958 SYSCTL_PCEEPROM — EEPROM Power Control
  [0] SYSCTL_PCEEPROM_P0 — EEPROM Module 0 Power Control
0x974 SYSCTL_PCCCM — CRC and Cryptographic Modules Power Control
  [0] SYSCTL_PCCCM_P0
0x990 SYSCTL_PCLCD — LCD Controller Power Control
  [0] SYSCTL_PCLCD_P0 — LCD Controller Module 0 Power Control
0x998 SYSCTL_PCOWIRE — 1-Wire Power Control
  [0] SYSCTL_PCOWIRE_P0 — 1-Wire Module 0 Power Control
0x99C SYSCTL_PCEMAC — Ethernet MAC Power Control
  [0] SYSCTL_PCEMAC_P0 — Ethernet MAC Module 0 Power Control
0x9A4 SYSCTL_PCHIM — Human Interface Master Power Control
  [0] SYSCTL_PCHIM_P0 — HIM Module 0 Power Control
0xA00 SYSCTL_PRWD ro — Watchdog Timer Peripheral Ready
  [1] SYSCTL_PRWD_R1 — Watchdog Timer 1 Peripheral Ready
  [0] SYSCTL_PRWD_R0 — Watchdog Timer 0 Peripheral Ready
0xA04 SYSCTL_PRTIMER ro — 16/32-Bit General-Purpose Timer Peripheral Ready
  [n] SYSCTL_PRTIMER_R{n} (n=0..7) — 16/32-Bit General-Purpose Timer {n} Peripheral Ready
0xA08 SYSCTL_PRGPIO ro — General-Purpose Input/Output Peripheral Ready
  [17] SYSCTL_PRGPIO_R17 — GPIO Port T Peripheral Ready
  [16] SYSCTL_PRGPIO_R16 — GPIO Port S Peripheral Ready
  [15] SYSCTL_PRGPIO_R15 — GPIO Port R Peripheral Ready
  [14] SYSCTL_PRGPIO_R14 — GPIO Port Q Peripheral Ready
  [13] SYSCTL_PRGPIO_R13 — GPIO Port P Peripheral Ready
  [12] SYSCTL_PRGPIO_R12 — GPIO Port N Peripheral Ready
  [11] SYSCTL_PRGPIO_R11 — GPIO Port M Peripheral Ready
  [10] SYSCTL_PRGPIO_R10 — GPIO Port L Peripheral Ready
  [9] SYSCTL_PRGPIO_R9 — GPIO Port K Peripheral Ready
  [8] SYSCTL_PRGPIO_R8 — GPIO Port J Peripheral Ready
  [7] SYSCTL_PRGPIO_R7 — GPIO Port H Peripheral Ready
  [6] SYSCTL_PRGPIO_R6 — GPIO Port G Peripheral Ready
  [5] SYSCTL_PRGPIO_R5 — GPIO Port F Peripheral Ready
  [4] SYSCTL_PRGPIO_R4 — GPIO Port E Peripheral Ready
  [3] SYSCTL_PRGPIO_R3 — GPIO Port D Peripheral Ready
  [2] SYSCTL_PRGPIO_R2 — GPIO Port C Peripheral Ready
  [1] SYSCTL_PRGPIO_R1 — GPIO Port B Peripheral Ready
  [0] SYSCTL_PRGPIO_R0 — GPIO Port A Peripheral Ready
0xA0C SYSCTL_PRDMA ro — Micro Direct Memory Access Peripheral Ready
  [0] SYSCTL_PRDMA_R0 — uDMA Module Peripheral Ready
0xA10 SYSCTL_PREPI ro — EPI Peripheral Ready
  [0] SYSCTL_PREPI_R0 — EPI Module Peripheral Ready
0xA14 SYSCTL_PRHIB ro — Hibernation Peripheral Ready
  [0] SYSCTL_PRHIB_R0 — Hibernation Module Peripheral Ready
0xA18 SYSCTL_PRUART ro — Universal Asynchronous Receiver/Transmitter Peripheral Ready
  [n] SYSCTL_PRUART_R{n} (n=0..7) — UART Module {n} Peripheral Ready
0xA1C SYSCTL_PRSSI ro — Synchronous Serial Interface Peripheral Ready
  [n] SYSCTL_PRSSI_R{n} (n=0..3) — SSI Module {n} Peripheral Ready
0xA20 SYSCTL_PRI2C ro — Inter-Integrated Circuit Peripheral Ready
  [n] SYSCTL_PRI2C_R{n} (n=0..9) — I2C Module {n} Peripheral Ready
0xA28 SYSCTL_PRUSB ro — Universal Serial Bus Peripheral Ready
  [0] SYSCTL_PRUSB_R0 — USB Module Peripheral Ready
0xA30 SYSCTL_PREPHY ro — Ethernet PHY Peripheral Ready
  [0] SYSCTL_PREPHY_R0 — Ethernet PHY Module Peripheral Ready
0xA34 SYSCTL_PRCAN ro — Controller Area Network Peripheral Ready
  [1] SYSCTL_PRCAN_R1 — CAN Module 1 Peripheral Ready
  [0] SYSCTL_PRCAN_R0 — CAN Module 0 Peripheral Ready
0xA38 SYSCTL_PRADC ro — Analog-to-Digital Converter Peripheral Ready
  [1] SYSCTL_PRADC_R1 — ADC Module 1 Peripheral Ready
  [0] SYSCTL_PRADC_R0 — ADC Module 0 Peripheral Ready
0xA3C SYSCTL_PRACMP ro — Analog Comparator Peripheral Ready
  [0] SYSCTL_PRACMP_R0 — Analog Comparator Module 0 Peripheral Ready
0xA40 SYSCTL_PRPWM ro — Pulse Width Modulator Peripheral Ready
  [0] SYSCTL_PRPWM_R0 — PWM Module 0 Peripheral Ready
0xA44 SYSCTL_PRQEI ro — Quadrature Encoder Interface Peripheral Ready
  [0] SYSCTL_PRQEI_R0 — QEI Module 0 Peripheral Ready
0xA48 SYSCTL_PRLPC ro — Low Pin Count Interface Peripheral Ready
  [0] SYSCTL_PRLPC_R0 — LPC Module Peripheral Ready
0xA50 SYSCTL_PRPECI ro — Platform Environment Control Interface Peripheral Ready
  [0] SYSCTL_PRPECI_R0 — PECI Module Peripheral Ready
0xA54 SYSCTL_PRFAN ro — Fan Peripheral Ready
  [1] SYSCTL_PRFAN_R1 — FAN Module 1 Peripheral Ready
  [0] SYSCTL_PRFAN_R0 — FAN Module Peripheral Ready
0xA58 SYSCTL_PREEPROM ro — EEPROM Peripheral Ready
  [0] SYSCTL_PREEPROM_R0 — EEPROM Module Peripheral Ready
0xA74 SYSCTL_PRCCM ro — CRC and Cryptographic Modules Peripheral Ready
  [0] SYSCTL_PRCCM_R0
0xA90 SYSCTL_PRLCD ro — LCD Controller Peripheral Ready
  [0] SYSCTL_PRLCD_R0 — LCD Controller Module 0 Peripheral Ready
0xA98 SYSCTL_PROWIRE ro — 1-Wire Peripheral Ready
  [0] SYSCTL_PROWIRE_R0 — 1-Wire Module 0 Peripheral Ready
0xA9C SYSCTL_PREMAC ro — Ethernet MAC Peripheral Ready
  [0] SYSCTL_PREMAC_R0 — Ethernet MAC Module 0 Peripheral Ready
0xAA4 SYSCTL_PRHIM ro — Human Interface Master Peripheral Ready
  [0] SYSCTL_PRHIM_R0 — HIM Module 0 Peripheral Ready
0x3F32204 SYSCTL_CCMCGREQ — Cryptographic Modules Clock Gating Request
  [2] SYSCTL_CCMCGREQ_DESCFG — DES Clock Gating Request
  [1] SYSCTL_CCMCGREQ_AESCFG — AES Clock Gating Request
  [0] SYSCTL_CCMCGREQ_SHACFG — SHA/MD5 Clock Gating Request
